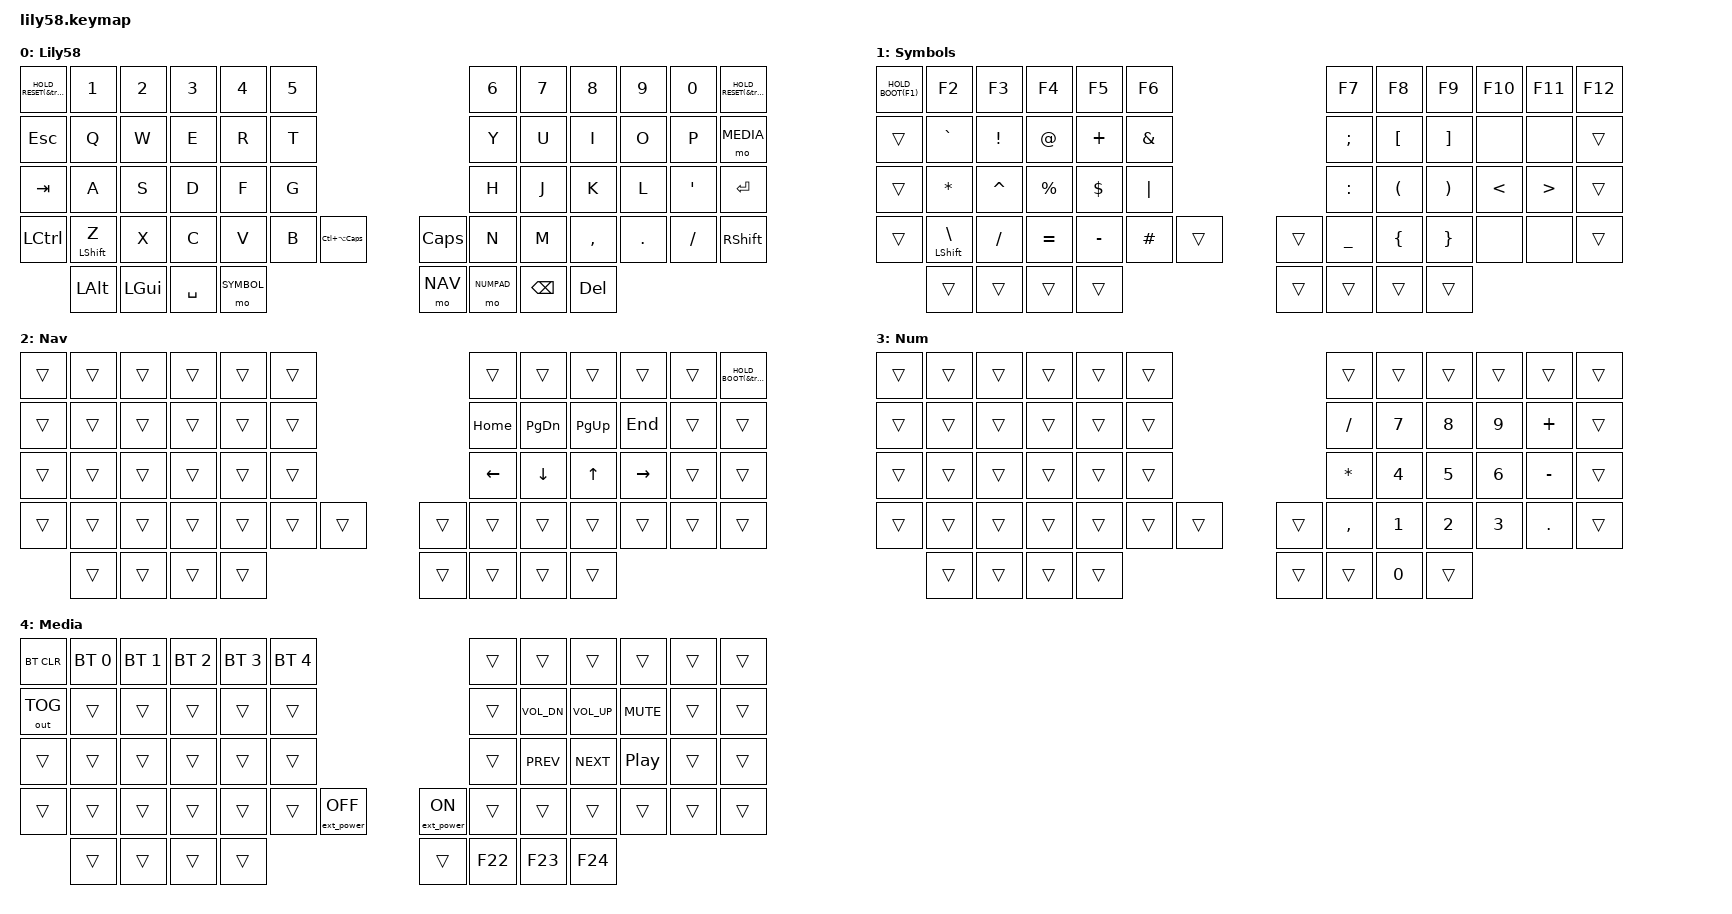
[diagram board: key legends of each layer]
/*
 * Copyright (c) 2020 The ZMK Contributors
 *
 * SPDX-License-Identifier: MIT
 */

#include <behaviors.dtsi>
#include <dt-bindings/zmk/keys.h>
#include <dt-bindings/zmk/bt.h>
#include <dt-bindings/zmk/ext_power.h>
#include <dt-bindings/zmk/behaviors.h>
#include <dt-bindings/zmk/outputs.h>

#define DEFAULT 0
#define SYMBOL  1
#define NAV    2
#define NUMPAD  3
#define MEDIA   4

#define HOLD_BOOT(key) &btldr_hold &trans key
#define HOLD_RESET(key) &reset_hold &trans key

/ {
        behaviors {
                btldr_hold: btldr_hold {
                        compatible = "zmk,behavior-hold-tap";
                        #binding-cells = <2>;
                        tapping-term-ms = <5000>;
                        flavor = "tap-preferred";
                        display-name = "Bootloader Hold";
                        bindings = <&bootloader>, <&kp>;
                };
                reset_hold: reset_hold {
                        compatible = "zmk,behavior-hold-tap";
                        #binding-cells = <2>;
                        tapping-term-ms = <5000>;
                        flavor = "tap-preferred";
                        display-name = "Reset Hold";
                        bindings = <&sys_reset>, <&kp>;
                };
        };
        combos {
                compatible = "zmk,combos";
                dongle_bootloader_left {
                        timeout-ms = <50>;
                        key-positions = <27 28 29>;
                        bindings = <&bootloader>;
                        layers = <SYMBOL>;
                };
                dongle_reset_left {
                        timeout-ms = <50>;
                        key-positions = <39 40 41>;
                        bindings = <&sys_reset>;
                        layers = <SYMBOL>;
                };
                dongle_bootloader_right {
                        timeout-ms = <50>;
                        key-positions = <30 31 32>;
                        bindings = <&bootloader>;
                        layers = <NAV>;
                };
                dongle_reset_right {
                        timeout-ms = <50>;
                        key-positions = <44 45 46>;
                        bindings = <&sys_reset>;
                        layers = <NAV>;
                };
        };

        keymap {
                compatible = "zmk,keymap";

                default_layer {
                        display-name = "Lily58";
                        bindings = <
   HOLD_RESET(&trans)  &kp N1       &kp N2   &kp N3    &kp N4    &kp N5                                      &kp N6   &kp N7     &kp N8    &kp N9    &kp N0    HOLD_RESET(&trans)
   &kp ESC             &kp Q        &kp W    &kp E     &kp R     &kp T                                       &kp Y    &kp U      &kp I     &kp O     &kp P     &mo MEDIA
   &kp TAB             &kp A        &kp S    &kp D     &kp F     &kp G                                       &kp H    &kp J      &kp K     &kp L     &kp SQT   &kp RET
   &kp LCTRL           &mt LSHFT Z  &kp X    &kp C     &kp V     &kp B       &kp LC(LA(CAPS))     &kp CAPS   &kp N    &kp M      &kp COMMA &kp DOT   &kp FSLH  &kp RSHFT
                          &kp LALT &kp LGUI  &kp SPACE &mo SYMBOL                                  &mo NAV &mo NUMPAD &kp BSPC  &kp DEL
                        >;
                };

                symbol_layer {
                        display-name = "Symbols";
                        bindings = <
   HOLD_BOOT(F1) &kp F2           &kp F3    &kp F4    &kp F5    &kp F6                        &kp F7    &kp F8    &kp F9    &kp F10  &kp F11  &kp F12
   &trans &kp GRAVE        &kp EXCL  &kp AT    &kp PLUS  &kp AMPS                      &kp SEMI  &kp LBKT  &kp RBKT  &none    &none    &trans
   &trans &kp ASTRK        &kp CARET &kp PRCNT &kp DLLR  &kp PIPE                      &kp COLON &kp LPAR  &kp RPAR  &kp LT   &kp GT   &trans
   &trans &mt LSHFT BSLH   &kp SLASH &kp EQUAL &kp MINUS &kp HASH &trans        &trans &kp UNDER &kp LBRC  &kp RBRC  &none    &none    &trans
                           &trans    &trans    &trans    &trans                        &trans    &trans    &trans    &trans
                        >;
                };

                navigation_layer {
                        display-name = "Nav";
                        bindings = <
   &trans    &trans    &trans    &trans   &trans   &trans                     &trans   &trans    &trans    &trans     &trans HOLD_BOOT(&trans)
   &trans    &trans    &trans    &trans   &trans   &trans                     &kp HOME &kp PG_DN &kp PG_UP &kp END    &trans &trans
   &trans    &trans    &trans    &trans   &trans   &trans                     &kp LEFT &kp DOWN  &kp UP    &kp RIGHT  &trans &trans
   &trans    &trans    &trans    &trans   &trans   &trans &trans       &trans &trans   &trans    &trans    &trans     &trans &trans
                       &trans    &trans   &trans   &trans                     &trans  &trans  &trans  &trans
                        >;
                };

                numpad_layer {
                        display-name = "Num";
                        bindings = <
   &trans  &trans  &trans  &trans  &trans  &trans                        &trans     &trans  &trans  &trans  &trans    &trans
   &trans  &trans  &trans  &trans  &trans  &trans                        &kp SLASH  &kp N7  &kp N8  &kp N9  &kp PLUS  &trans
   &trans  &trans  &trans  &trans  &trans  &trans                        &kp ASTRK  &kp N4  &kp N5  &kp N6  &kp MINUS &trans
   &trans  &trans  &trans  &trans  &trans  &trans &trans          &trans &kp COMMA  &kp N1  &kp N2  &kp N3  &kp DOT   &trans
                   &trans  &trans  &trans  &trans                        &trans     &trans  &kp N0  &trans
                        >;
                };

                media_layer {
                        display-name = "Media";
                        bindings = <
   &bt BT_CLR    &bt BT_SEL 0 &bt BT_SEL 1 &bt BT_SEL 2 &bt BT_SEL 3 &bt BT_SEL 4                                    &trans   &trans        &trans        &trans           &trans  &trans
   &out OUT_TOG  &trans       &trans       &trans       &trans       &trans                                          &trans   &kp C_VOL_DN  &kp C_VOL_UP  &kp C_MUTE       &trans  &trans
   &trans        &trans       &trans       &trans       &trans       &trans                                          &trans   &kp C_PREV    &kp C_NEXT    &kp C_PLAY_PAUSE &trans  &trans
   &trans        &trans       &trans       &trans       &trans       &trans       &ext_power EP_OFF &ext_power EP_ON &trans   &trans        &trans        &trans           &trans  &trans
                              &trans       &trans       &trans       &trans                                          &trans   &kp F22       &kp F23       &kp F24 
                        >;
                };
        };
};
